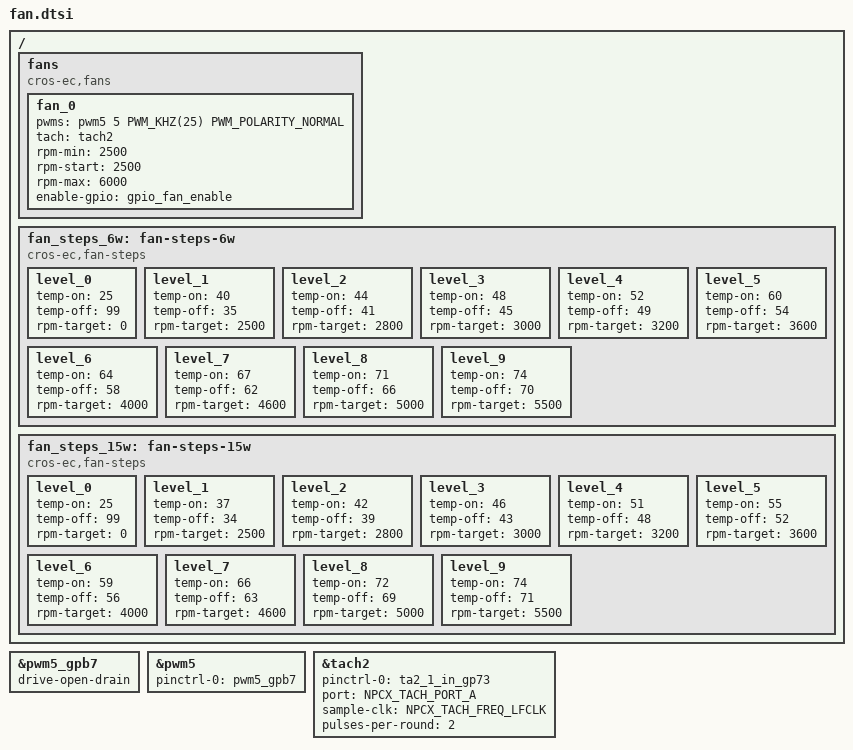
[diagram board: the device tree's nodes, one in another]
/* Copyright 2022 The ChromiumOS Authors
 * Use of this source code is governed by a BSD-style license that can be
 * found in the LICENSE file.
 */
/ {
	fans {
		compatible = "cros-ec,fans";
		fan_0 {
			pwms = <&pwm5 5 PWM_KHZ(25) PWM_POLARITY_NORMAL>;
			tach = <&tach2>;
			rpm-min = <2500>;
			rpm-start = <2500>;
			rpm-max = <6000>;
			enable-gpio = <&gpio_fan_enable>;
		};
	};

	fan_steps_6w: fan-steps-6w {
		compatible = "cros-ec,fan-steps";
		level_0 {
			temp-on = <25>;
			temp-off = <99>;
			rpm-target = <0>;
		};
		level_1 {
			temp-on = <40>;
			temp-off = <35>;
			rpm-target = <2500>;
		};
		level_2 {
			temp-on = <44>;
			temp-off = <41>;
			rpm-target = <2800>;
		};
		level_3 {
			temp-on = <48>;
			temp-off = <45>;
			rpm-target = <3000>;
		};
		level_4 {
			temp-on = <52>;
			temp-off = <49>;
			rpm-target = <3200>;
		};
		level_5 {
			temp-on = <60>;
			temp-off = <54>;
			rpm-target = <3600>;
		};
		level_6 {
			temp-on = <64>;
			temp-off = <58>;
			rpm-target = <4000>;
		};
		level_7 {
			temp-on = <67>;
			temp-off = <62>;
			rpm-target = <4600>;
		};
		level_8 {
			temp-on = <71>;
			temp-off = <66>;
			rpm-target = <5000>;
		};
		level_9 {
			temp-on = <74>;
			temp-off = <70>;
			rpm-target = <5500>;
		};
	};

	fan_steps_15w: fan-steps-15w {
		compatible = "cros-ec,fan-steps";
		level_0 {
			temp-on = <25>;
			temp-off = <99>;
			rpm-target = <0>;
		};
		level_1 {
			temp-on = <37>;
			temp-off = <34>;
			rpm-target = <2500>;
		};
		level_2 {
			temp-on = <42>;
			temp-off = <39>;
			rpm-target = <2800>;
		};
		level_3 {
			temp-on = <46>;
			temp-off = <43>;
			rpm-target = <3000>;
		};
		level_4 {
			temp-on = <51>;
			temp-off = <48>;
			rpm-target = <3200>;
		};
		level_5 {
			temp-on = <55>;
			temp-off = <52>;
			rpm-target = <3600>;
		};
		level_6 {
			temp-on = <59>;
			temp-off = <56>;
			rpm-target = <4000>;
		};
		level_7 {
			temp-on = <66>;
			temp-off = <63>;
			rpm-target = <4600>;
		};
		level_8 {
			temp-on = <72>;
			temp-off = <69>;
			rpm-target = <5000>;
		};
		level_9 {
			temp-on = <74>;
			temp-off = <71>;
			rpm-target = <5500>;
		};
	};
};

&pwm5_gpb7 {
	drive-open-drain;
};

/* pwm for fan */
&pwm5 {
	status = "okay";
	pinctrl-0 = <&pwm5_gpb7>;
	pinctrl-names = "default";
};

/* Tachometer for fan speed measurement */
&tach2 {
	status = "okay";
	pinctrl-0 = <&ta2_1_in_gp73>;
	pinctrl-names = "default";
	port = <NPCX_TACH_PORT_A>; /* port-A is selected */
	sample-clk = <NPCX_TACH_FREQ_LFCLK>; /* Use LFCLK as sampling clock */
	pulses-per-round = <2>; /* number of pulses per round of encoder */
};
